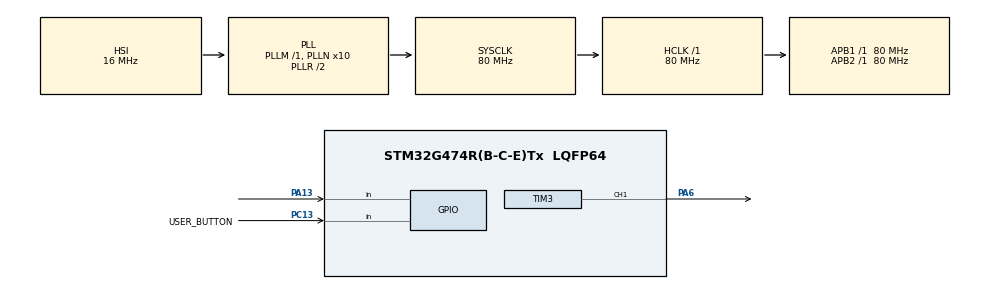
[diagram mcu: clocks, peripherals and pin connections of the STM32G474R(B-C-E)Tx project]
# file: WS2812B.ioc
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Dma.Request0=TIM3_CH1
Dma.TIM3_CH1.0.Direction=DMA_PERIPH_TO_MEMORY
Dma.TIM3_CH1.0.EventEnable=DISABLE
Dma.TIM3_CH1.0.Instance=DMA1_Channel1
Dma.TIM3_CH1.0.MemDataAlignment=DMA_MDATAALIGN_BYTE
Dma.TIM3_CH1.0.MemInc=DMA_MINC_ENABLE
Dma.TIM3_CH1.0.Mode=DMA_NORMAL
Dma.TIM3_CH1.0.PeriphDataAlignment=DMA_PDATAALIGN_HALFWORD
Dma.TIM3_CH1.0.PeriphInc=DMA_PINC_DISABLE
Dma.TIM3_CH1.0.Polarity=HAL_DMAMUX_REQ_GEN_RISING
Dma.TIM3_CH1.0.Priority=DMA_PRIORITY_LOW
Dma.TIM3_CH1.0.RequestNumber=1
Dma.TIM3_CH1.0.SignalID=NONE
Dma.TIM3_CH1.0.SyncEnable=DISABLE
Dma.TIM3_CH1.0.SyncPolarity=HAL_DMAMUX_SYNC_NO_EVENT
Dma.TIM3_CH1.0.SyncRequestNumber=1
Dma.TIM3_CH1.0.SyncSignalID=NONE
Mcu.Family=STM32G4
Mcu.Name=STM32G474R(B-C-E)Tx
Mcu.Package=LQFP64
NVIC.DMA1_Channel1_IRQn=true\:0\:0\:false\:false\:true\:false\:true\:true
NVIC.PriorityGroup=NVIC_PRIORITYGROUP_4
NVIC.TIM2_IRQn=true\:0\:0\:false\:false\:true\:true\:true\:true
PA13.Signal=GPIO_Input
PA6.Signal=S_TIM3_CH1
PC13.GPIO_Label=USER_BUTTON
PC13.Signal=GPIO_Input
ProjectManager.HeapSize=0x200
ProjectManager.StackSize=0x400
ProjectManager.TargetToolchain=STM32CubeIDE
RCC.ADC12Freq_Value=80000000
RCC.ADC345Freq_Value=80000000
RCC.AHBFreq_Value=80000000
RCC.APB1Freq_Value=80000000
RCC.APB1TimFreq_Value=80000000
RCC.APB2Freq_Value=80000000
RCC.APB2TimFreq_Value=80000000
RCC.CortexFreq_Value=80000000
RCC.EXTERNAL_CLOCK_VALUE=12288000
RCC.HCLKFreq_Value=80000000
RCC.HSE_VALUE=8000000
RCC.HSI48_VALUE=48000000
RCC.HSI_VALUE=16000000
RCC.LSE_VALUE=32768
RCC.PLLN=10
RCC.SYSCLKFreq_VALUE=80000000
RCC.SYSCLKSource=RCC_SYSCLKSOURCE_PLLCLK
RCC.USBFreq_Value=80000000
RCC.VCOOutputFreq_Value=160000000
SH.S_TIM3_CH1.0=TIM3_CH1,PWM Generation1 CH1
TIM2.PeriodNoDither=999
TIM2.Prescaler=7999
TIM3.Channel-PWM\ Generation1\ CH1=TIM_CHANNEL_1
TIM3.PeriodNoDither=99
VP_SYS_VS_DBSignals.Mode=DisableDeadBatterySignals
VP_TIM2_VS_ClockSourceINT.Mode=Internal
VP_TIM3_VS_ClockSourceINT.Mode=Internal
board=custom

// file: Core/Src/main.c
/* USER CODE BEGIN Header */
/**
  ******************************************************************************
  * @file           : main.c
  * @brief          : Main program body
  ******************************************************************************
  * @attention
  *
  * Copyright (c) 2024 STMicroelectronics.
  * All rights reserved.
  *
  * This software is licensed under terms that can be found in the LICENSE file
  * in the root directory of this software component.
  * If no LICENSE file comes with this software, it is provided AS-IS.
  *
  ******************************************************************************
  */
/* USER CODE END Header */
#include "main.h"
#include "dma.h"
#include "tim.h"
#include "gpio.h"

/* USER CODE BEGIN Includes */
#include "ws2812b.h"
/* USER CODE END Includes */

/* USER CODE BEGIN PV */
uint8_t red_state = 0;
uint8_t green_intensity = 0;
uint16_t cycle_step = 0; // Licznik kroków w cyklu narastania sygnału piłokształtnego dla zielonej diody
uint8_t blink_active = 0; // Flaga ustawiana w przerwaniu od przycisku
uint8_t blink_count = 0;
uint32_t last_time = 0;

/* USER CODE END PV */

void SystemClock_Config(void);

/* USER CODE BEGIN 0 */
void HAL_TIM_PeriodElapsedCallback(TIM_HandleTypeDef *htim) // Funkcja realizująca temat zadania
{
	// TIM2 generuje przerwanie co 10ms
    if (htim == &htim2) {
        uint32_t current_time = HAL_GetTick();

        // Obsługa prostokątnej zmiany R co 1,5 s
        if ((current_time - last_time) >= 1500) {
            red_state = !red_state;  // Zmieniaj stan R
            last_time = current_time;
        }
        uint8_t red_value = red_state ? 255 : 0;

        // Obsługa piłokształtnej zmiany G -> 300 cykli = 3s,
        if (cycle_step < 300) { // Faza wzrostu
            green_intensity = (cycle_step * 255) / 300; // Zwiększ intensywność od 0 do 255 przez 300 kroków
        } else {
            green_intensity = 0; // Natychmiastowy spadek do 0
        }

        // Zwiększ krok cyklu
        cycle_step++;
        if (cycle_step >= 300) { // Resetuj po pełnym cyklu
            cycle_step = 0;
        }

        // Obsługa mrugania B przy aktywnej fladze blink ustawianej w przerwaniu od przycisku
        uint8_t b_value = 0;
        if (blink_active) {
            b_value = (blink_count % 2) ? 255 : 0;
            blink_count--;
            if (blink_count == 0) {
                blink_active = 0;
            }
        }

        ws2812b_set_color(0, red_value, green_intensity, b_value);
        ws2812b_update();
    }
}

void HAL_GPIO_EXTI_Callback(uint16_t GPIO_Pin)
{
    if (GPIO_Pin == USER_BUTTON_Pin) // Przerwanie od przycisku
    {
        blink_active = 1; // flaga do sterowania diodą
        blink_count = 6;  // 3 mrugnięcia, łącznie 6 zmian (ON-OFF)
    }
}

/* USER CODE END 0 */

int main(void)
{

  /* MCU Configuration--------------------------------------------------------*/

  /* Reset of all peripherals, Initializes the Flash interface and the Systick. */
  HAL_Init();

  /* Configure the system clock */
  SystemClock_Config();

  /* Initialize all configured peripherals */
  MX_GPIO_Init();
  MX_DMA_Init();
  MX_TIM3_Init();
  MX_TIM2_Init();
  HAL_TIM_Base_Start_IT(&htim2); // Włączenie przerwań dla TIM2

  /* USER CODE BEGIN 2 */
  ws2812b_init(); // Inicjalizacja biblioteki do obsługi ws2812b
  /* USER CODE END 2 */

  /* Infinite loop */
  while (1)
  {

  }
}

void SystemClock_Config(void)
{
  RCC_OscInitTypeDef RCC_OscInitStruct = {0};
  RCC_ClkInitTypeDef RCC_ClkInitStruct = {0};

  /** Configure the main internal regulator output voltage
  */
  HAL_PWREx_ControlVoltageScaling(PWR_REGULATOR_VOLTAGE_SCALE1);

  /** Initializes the RCC Oscillators according to the specified parameters
  * in the RCC_OscInitTypeDef structure.
  */
  RCC_OscInitStruct.OscillatorType = RCC_OSCILLATORTYPE_HSI;
  RCC_OscInitStruct.HSIState = RCC_HSI_ON;
  RCC_OscInitStruct.HSICalibrationValue = RCC_HSICALIBRATION_DEFAULT;
  RCC_OscInitStruct.PLL.PLLState = RCC_PLL_ON;
  RCC_OscInitStruct.PLL.PLLSource = RCC_PLLSOURCE_HSI;
  RCC_OscInitStruct.PLL.PLLM = RCC_PLLM_DIV1;
  RCC_OscInitStruct.PLL.PLLN = 10;
  RCC_OscInitStruct.PLL.PLLP = RCC_PLLP_DIV2;
  RCC_OscInitStruct.PLL.PLLQ = RCC_PLLQ_DIV2;
  RCC_OscInitStruct.PLL.PLLR = RCC_PLLR_DIV2;
  if (HAL_RCC_OscConfig(&RCC_OscInitStruct) != HAL_OK)
  {
    Error_Handler();
  }

  /** Initializes the CPU, AHB and APB buses clocks
  */
  RCC_ClkInitStruct.ClockType = RCC_CLOCKTYPE_HCLK|RCC_CLOCKTYPE_SYSCLK
                              |RCC_CLOCKTYPE_PCLK1|RCC_CLOCKTYPE_PCLK2;
  RCC_ClkInitStruct.SYSCLKSource = RCC_SYSCLKSOURCE_PLLCLK;
  RCC_ClkInitStruct.AHBCLKDivider = RCC_SYSCLK_DIV1;
  RCC_ClkInitStruct.APB1CLKDivider = RCC_HCLK_DIV1;
  RCC_ClkInitStruct.APB2CLKDivider = RCC_HCLK_DIV1;

  if (HAL_RCC_ClockConfig(&RCC_ClkInitStruct, FLASH_LATENCY_2) != HAL_OK)
  {
    Error_Handler();
  }
}

void Error_Handler(void)
{
  __disable_irq();
  while (1)
  {
  }
}
